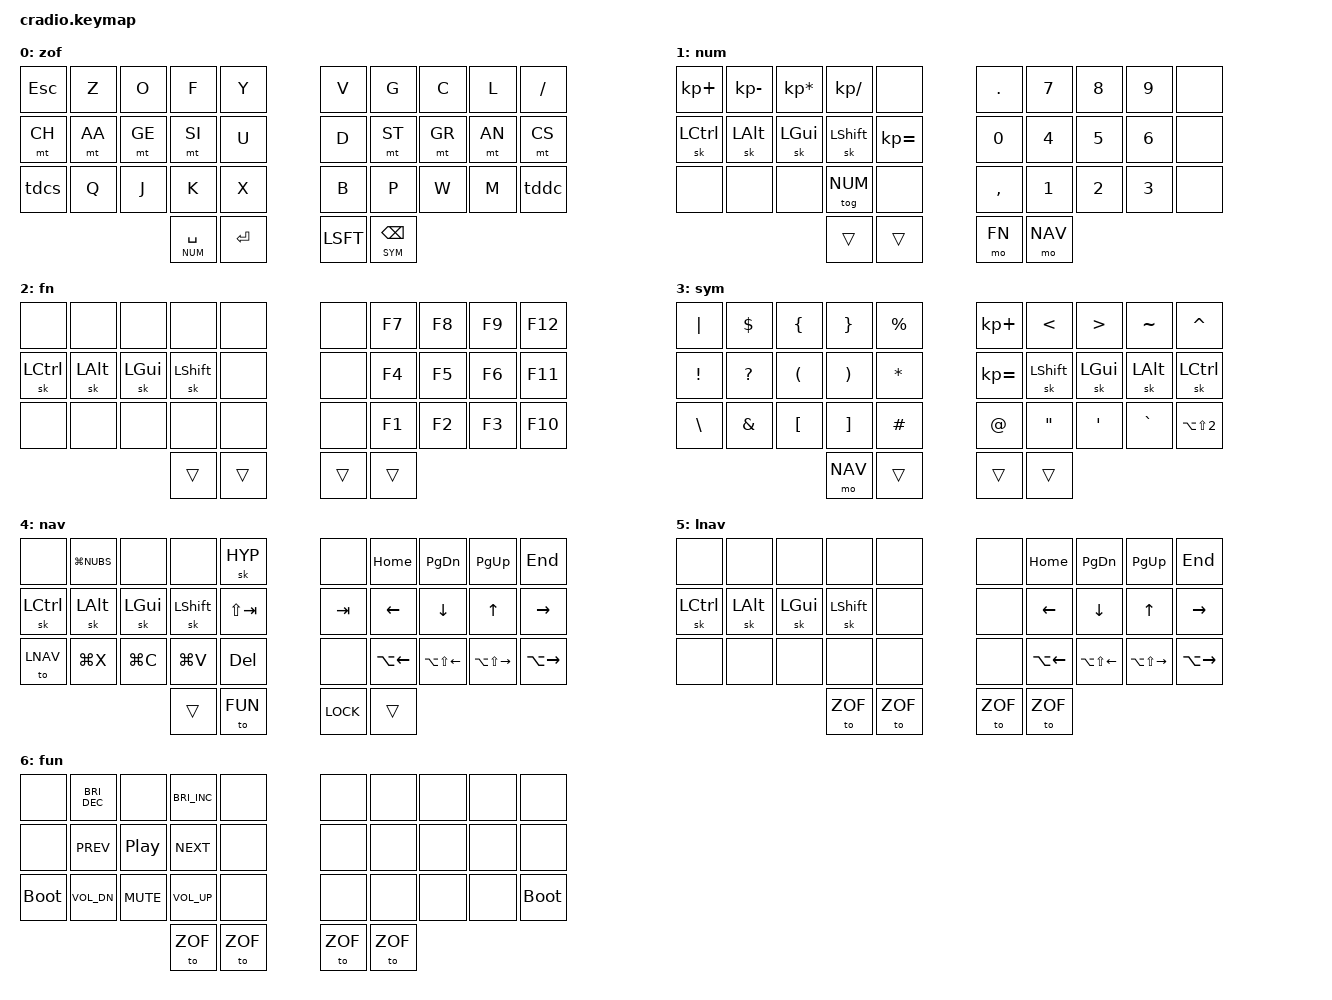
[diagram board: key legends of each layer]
/*
 * Copyright (c) 2020 The ZMK Contributors
 *
 * SPDX-License-Identifier: MIT
 */

#include <behaviors.dtsi>
#include <dt-bindings/zmk/keys.h>
#include <dt-bindings/zmk/bt.h>

// timeouts
#define COMBO_TIMEOUT 100
#define DEFAULT_TAP_TERM 200
#define DOUBLE_TAP_TERM 300
#define MOD_TAP_TERM DEFAULT_TAP_TERM
#define LAYER_TAP_TERM 200
#define QUICK_TAP_TERM 125
#define STICKY_KEYS_TIMEOUT 2000

// layers
#define ZOF 0
#define NUM 1
#define FN 2
#define SYM 3
#define NAV 4
#define LNAV 5
#define FUN 6

// modifier combinations
#define HYP LG(LS(LA(LCTRL)))

// special mac combinations
#define LOCK LG(LC(Q))

// mod-tap combinations
#define CH LCTRL H
#define AA LALT A
#define GE LGUI E
#define SI LSHFT I

#define CS LCTRL S
#define AN LALT N
#define GR LGUI R
#define ST LSHFT T

// helper for easier and shorter combo definitions
#define COMBO(NAME, BINDINGS, TIMEOUT, KEYPOS) \
  combo_##NAME { \
    timeout-ms = <TIMEOUT>; \
    bindings = <BINDINGS>; \
    key-positions = <KEYPOS>; \
    layers = <0>; \
  };

// mod-tap config
&mt {
  flavor = "tap-preferred";
  tapping_term_ms = <MOD_TAP_TERM>;
};

// caps-word config
&caps_word {
    continue-list = <UNDERSCORE MINUS BACKSPACE>;
};

// sticky-key config
&sk {
    release-after-ms = <STICKY_KEYS_TIMEOUT>;
};

/ {
    macros {
      tridot: tripple_dot {
        label = "tripple_dot";
        compatible = "zmk,behavior-macro";
        #binding-cells = <0>;
        bindings = <&kp DOT &kp DOT &kp DOT>;
      };
    };
  
    combos {
      compatible = "zmk,combos";

      COMBO(hypr, &sk HYP, COMBO_TIMEOUT, 4 5)
      COMBO(caps, &caps_word, COMBO_TIMEOUT, 20 29)
      COMBO(undo, &kp LG(Z), COMBO_TIMEOUT, 0 9)
      COMBO(tab, &kp TAB, COMBO_TIMEOUT, 14 15)
      COMBO(del, &kp DEL, COMBO_TIMEOUT, 24 25)
      COMBO(minus, &kp MINUS, COMBO_TIMEOUT, 23 26)
      COMBO(underscore, &kp UNDER, COMBO_TIMEOUT, 22 27)
    };

    behaviors {
      gqt: global-quick-tap {
        compatible = "zmk,behavior-hold-tap";
        label = "GLOBAL_QUICK_TAP";
        #binding-cells = <2>;
        flavor = "tap-preferred";
        tapping-term-ms = <DEFAULT_TAP_TERM>;
        quick-tap-ms = <QUICK_TAP_TERM>;
        global-quick-tap;
        bindings = <&kp>, <&kp>;
      };

      tddc: dot-tap-dance {
        compatible = "zmk,behavior-tap-dance";
        label = "DOT_TAP_DANCE";
        #binding-cells = <0>;
        tapping-term-ms = <DOUBLE_TAP_TERM>;
        bindings = <&kp DOT>, <&kp COLON>, <&tridot>;
      };

      tdcs: com-tap-dance {
        compatible = "zmk,behavior-tap-dance";
        label = "COM_TAP_DANCE";
        #binding-cells = <0>;
        tapping-term-ms = <DOUBLE_TAP_TERM>;
        bindings = <&kp COMMA>, <&kp SEMI>;
      };
    };

    keymap {
      compatible = "zmk,keymap";

      // 0 - updated ZOF for less keys
      zof {
        bindings = <
          &kp ESC  &kp Z   &kp O   &kp F       &kp Y        &kp V    &kp G        &kp C   &kp L   &kp SLASH
          &mt CH   &mt AA  &mt GE  &mt SI      &kp U        &kp D    &mt ST       &mt GR  &mt AN  &mt CS
          &tdcs    &kp Q   &kp J   &kp K       &kp X		    &kp B    &kp P        &kp W   &kp M   &tddc
                                   &lt NUM SPC &kp RET      &kp LSFT &lt SYM BKSP
        >;
		  };

      // 1 - numbers and symbols
      num {
        bindings = <
          &kp KP_PLUS &kp KP_MINUS &kp KP_MULTIPLY &kp KP_DIVIDE &none            &kp DOT   &kp N7  &kp N8 &kp N9 &none
          &sk LCTRL   &sk LALT     &sk LGUI        &sk LSHFT     &kp KP_EQUAL     &kp N0    &kp N4  &kp N5 &kp N6 &none
          &none       &none        &none           &tog NUM      &none            &kp COMMA &kp N1  &kp N2 &kp N3 &none
                                                   &trans        &trans           &mo FN    &mo NAV 
        >;
      };

      // 2 - f1-f12
      fn {
        bindings = <
          &none     &none    &none    &none     &none     &none  &kp F7  &kp F8 &kp F9 &kp F12
          &sk LCTRL &sk LALT &sk LGUI &sk LSHFT &none     &none  &kp F4  &kp F5 &kp F6 &kp F11
          &none     &none    &none    &none     &none     &none  &kp F1  &kp F2 &kp F3 &kp F10
                                      &trans    &trans    &trans &trans
        >;
		  };
		
      // 3 - symbols
		  sym {
        bindings = <
          &kp PIPE &kp DLLR  &kp LBRC &kp RBRC &kp PRCNT      &kp KP_PLUS  &kp LT    &kp GT   &kp TILDE &kp CARET
          &kp EXCL &kp QMARK &kp LPAR &kp RPAR &kp ASTRK      &kp KP_EQUAL &sk LSHFT &sk LGUI &sk LALT  &sk LCTRL
          &kp BSLH &kp AMPS  &kp LBKT &kp RBKT &kp HASH       &kp AT       &kp DQT   &kp SQT  &kp GRAVE &kp LA(LS(N2))
                                      &mo NAV  &trans         &trans       &trans 
        >;
		  };	

      // 4 - navigation
		  nav {
        bindings = <
          &none     &kp LG(NUBS) &none     &none     &sk HYP         &none    &kp HOME     &kp PG_DN         &kp PG_UP         &kp END
          &sk LCTRL &sk LALT     &sk LGUI  &sk LSHFT &kp LS(TAB)     &kp TAB  &kp LEFT     &kp DOWN          &kp UP            &kp RIGHT
          &to LNAV  &kp LG(X)    &kp LG(C) &kp LG(V) &kp DEL         &none    &kp LA(LEFT) &kp LA(LS(LEFT))  &kp LA(LS(RIGHT)) &kp LA(RIGHT)
                                           &trans    &to FUN         &kp LOCK &trans
        >;
		  };

      // 4 - lockable reduced navigation layer (workaround)
      // can be removed, when there's a solution for https://github.com/zmkfirmware/zmk/issues/1299
		  lnav {
        bindings = <
          &none     &none    &none    &none     &none         &none   &kp HOME     &kp PG_DN         &kp PG_UP         &kp END
          &sk LCTRL &sk LALT &sk LGUI &sk LSHFT &none         &none   &kp LEFT     &kp DOWN          &kp UP            &kp RIGHT
          &none     &none    &none    &none     &none         &none   &kp LA(LEFT) &kp LA(LS(LEFT))  &kp LA(LS(RIGHT)) &kp LA(RIGHT)
                                      &to ZOF   &to ZOF       &to ZOF &to ZOF
        >;
		  };
		
      // 5 - media functions etc.
		  fun {
        bindings = <
          &none       &kp C_BRI_DEC &none      &kp C_BRI_INC &none       &none   &none   &none &none &none
          &none       &kp C_PREV    &kp C_PP   &kp C_NEXT    &none       &none   &none   &none &none &none
          &bootloader &kp C_VOL_DN  &kp C_MUTE &kp C_VOL_UP  &none       &none   &none   &none &none &bootloader
                                               &to ZOF       &to ZOF     &to ZOF &to ZOF
        >;
		  };

      // empty template
		  // empty {
      //   bindings = <
      //     &none &none &none &none &none     &none &none &none &none &none
      //     &none &none &none &none &none     &none &none &none &none &none
      //     &none &none &none &none &none     &none &none &none &none &none
      //                       &none &none     &none &none
      //   >;
		  // };
	};
};
